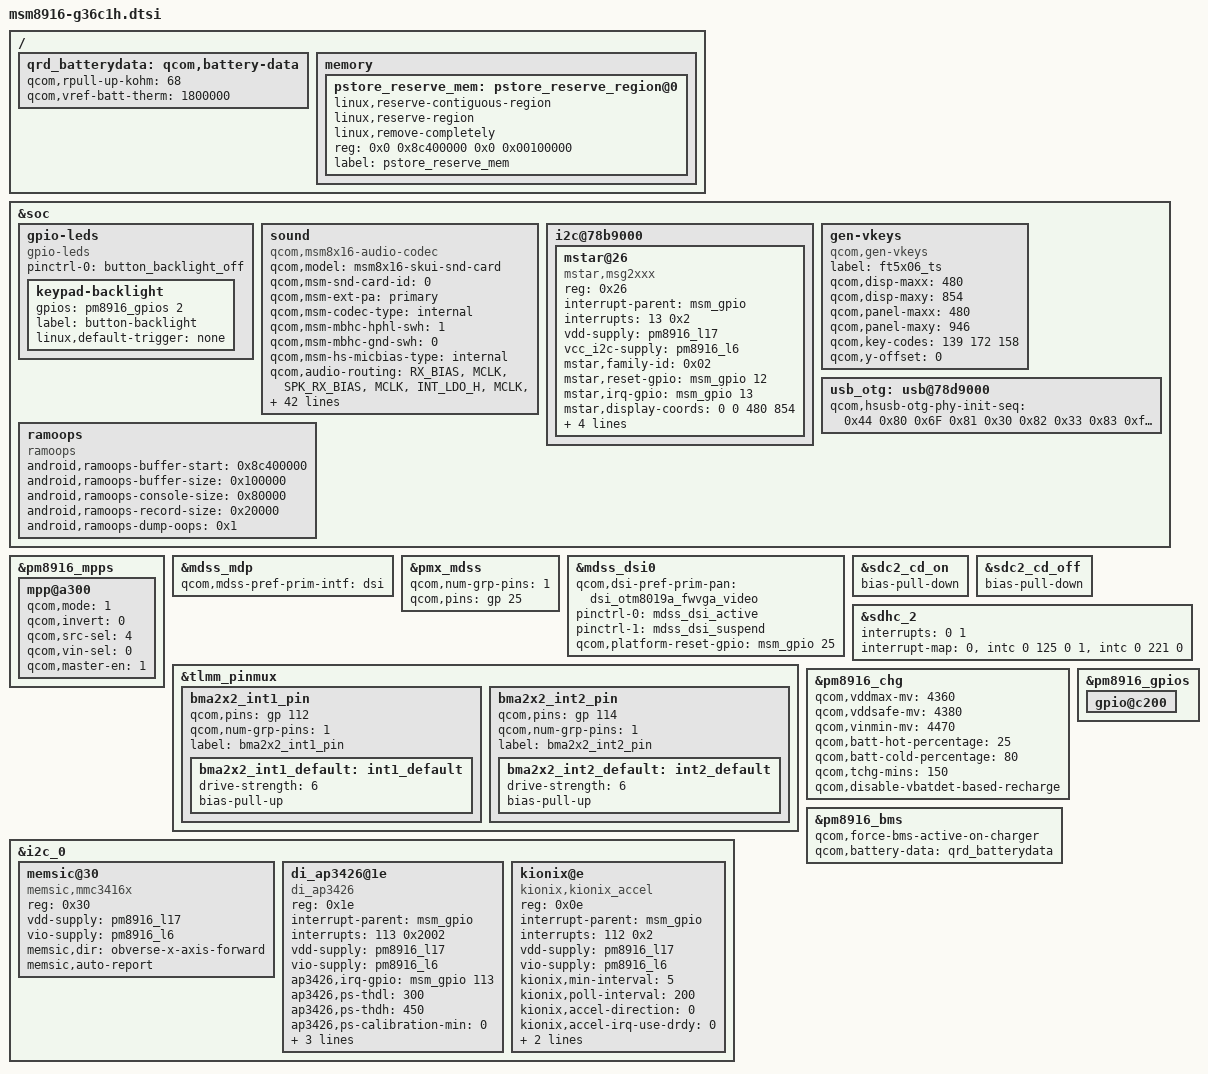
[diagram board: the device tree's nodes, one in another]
/* Copyright (c) 2014, The Linux Foundation. All rights reserved.
 *
 * This program is free software; you can redistribute it and/or modify
 * it under the terms of the GNU General Public License version 2 and
 * only version 2 as published by the Free Software Foundation.
 *
 * This program is distributed in the hope that it will be useful,
 * but WITHOUT ANY WARRANTY; without even the implied warranty of
 * MERCHANTABILITY or FITNESS FOR A PARTICULAR PURPOSE.  See the
 * GNU General Public License for more details.
 */

#include "msm8916-camera-sensor-g36c1h.dtsi"
#include "dsi-panel-ili9806e-fwvga-hsd-helitai-video.dtsi"

&soc {
	gpio-leds {
		compatible = "gpio-leds";
		status = "okay";
		pinctrl-names = "default";
		pinctrl-0 = <&button_backlight_off>;

		keypad-backlight {
			gpios = <&msm_gpio 119 0>;
			label = "button-backlight";
			linux,default-trigger = "none";
		};
	};

	sound {
		compatible = "qcom,msm8x16-audio-codec";
		qcom,model = "msm8x16-skui-snd-card";
		qcom,msm-snd-card-id = <0>;
		qcom,msm-ext-pa = "primary";
		qcom,msm-codec-type = "internal";
		qcom,msm-mbhc-hphl-swh = <1>;
		qcom,msm-mbhc-gnd-swh = <0>;
		qcom,msm-hs-micbias-type = "internal";
		qcom,audio-routing =
			"RX_BIAS", "MCLK",
			"SPK_RX_BIAS", "MCLK",
			"INT_LDO_H", "MCLK",
			"MIC BIAS Internal1", "Handset Mic",
			"MIC BIAS Internal2", "Headset Mic",
			"MIC BIAS Internal1", "Secondary Mic",
			"AMIC1", "MIC BIAS Internal1",
			"AMIC2", "MIC BIAS Internal2",
			"AMIC3", "MIC BIAS Internal1";
		pinctrl-names = "cdc_lines_act",
				"cdc_lines_sus";
		pinctrl-0 = <&cdc_pdm_lines_act>;
		pinctrl-1 = <&cdc_pdm_lines_sus>;
		asoc-platform = <&pcm0>, <&pcm1>, <&voip>, <&voice>,
				<&loopback>, <&compress>, <&hostless>,
				<&afe>, <&lsm>, <&routing>, <&lpa>;
		asoc-platform-names = "msm-pcm-dsp.0", "msm-pcm-dsp.1",
				"msm-voip-dsp", "msm-pcm-voice", "msm-pcm-loopback",
				"msm-compress-dsp", "msm-pcm-hostless", "msm-pcm-afe",
				"msm-lsm-client", "msm-pcm-routing", "msm-pcm-lpa";
		asoc-cpu = <&dai_pri_auxpcm>, <&dai_hdmi>,
				<&dai_mi2s0>, <&dai_mi2s1>, <&dai_mi2s2>, <&dai_mi2s3>,
				<&sb_0_rx>, <&sb_0_tx>, <&sb_1_rx>, <&sb_1_tx>,
				<&sb_3_rx>, <&sb_3_tx>, <&sb_4_rx>, <&sb_4_tx>,
				<&bt_sco_rx>, <&bt_sco_tx>, <&bt_a2dp_rx>,
				<&int_fm_rx>, <&int_fm_tx>,
				<&afe_pcm_rx>, <&afe_pcm_tx>, <&afe_proxy_rx>, <&afe_proxy_tx>,
				<&incall_record_rx>, <&incall_record_tx>, <&incall_music_rx>,
				<&incall_music_2_rx>;
		asoc-cpu-names = "msm-dai-q6-auxpcm.1", "msm-dai-q6-hdmi.8",
				"msm-dai-q6-mi2s.0", "msm-dai-q6-mi2s.1",
				"msm-dai-q6-mi2s.2", "msm-dai-q6-mi2s.3",
				"msm-dai-q6-dev.16384", "msm-dai-q6-dev.16385",
				"msm-dai-q6-dev.16386", "msm-dai-q6-dev.16387",
				"msm-dai-q6-dev.16390", "msm-dai-q6-dev.16391",
				"msm-dai-q6-dev.16392", "msm-dai-q6-dev.16393",
				"msm-dai-q6-dev.12288", "msm-dai-q6-dev.12289",
				"msm-dai-q6-dev.12290", "msm-dai-q6-dev.12292",
				"msm-dai-q6-dev.12293", "msm-dai-q6-dev.224",
				"msm-dai-q6-dev.225", "msm-dai-q6-dev.241",
				"msm-dai-q6-dev.240", "msm-dai-q6-dev.32771",
				"msm-dai-q6-dev.32772", "msm-dai-q6-dev.32773",
				"msm-dai-q6-dev.32770";
		asoc-codec = <&stub_codec>, <&pm8916_tombak_dig>;
		asoc-codec-names = "msm-stub-codec.1", "tombak_codec";
	};

	i2c@78b9000 { /* BLSP1 QUP5 */
		mstar@26{
			compatible = "mstar,msg213xa";
			reg = <0x26>;
			interrupt-parent = <&msm_gpio>;
			interrupts = <13 0x2>;
			vdd-supply = <&pm8916_l17>;
			vcc_i2c-supply = <&pm8916_l6>;
			mstar,family-id = <0x02>;
			mstar,reset-gpio = <&msm_gpio 12 0x00>;
			mstar,irq-gpio = <&msm_gpio 13 0x00>;
			mstar,display-coords = <0 0 480 854>;
			mstar,panel-coords = <0 0 480 946>;
			mstar,button-map= <158 102 139>;
			mstar,no-force-update;
			mstar,i2c-pull-up;
		};
		mstar@26{
			compatible = "mstar,msg26xx";
			reg = <0x26>;
			interrupt-parent = <&msm_gpio>;
			interrupts = <13 0x2>;
			vdd-supply = <&pm8916_l17>;
			vcc_i2c-supply = <&pm8916_l6>;
			mstar,family-id = <0x02>;
			mstar,reset-gpio = <&msm_gpio 12 0x00>;
			mstar,irq-gpio = <&msm_gpio 13 0x00>;
			mstar,display-coords = <0 0 720 1280>;
			mstar,panel-coords = <0 0 720 1380>;
			mstar,button-map= <139 172 158>;
			mstar,no-force-update;
			mstar,i2c-pull-up;
		};
		mstar@26{
			compatible = "mstar,msg2xxx";
			reg = <0x26>;
			interrupt-parent = <&msm_gpio>;
			interrupts = <13 0x2>;
			vdd-supply = <&pm8916_l17>;
			vcc_i2c-supply = <&pm8916_l6>;
			mstar,family-id = <0x02>;
			mstar,reset-gpio = <&msm_gpio 12 0x00>;
			mstar,irq-gpio = <&msm_gpio 13 0x00>;
			mstar,display-coords = <0 0 480 854>;
			mstar,panel-coords = <0 0 480 946>;
			mstar,button-map= <580 158 172>;
			mstar,no-force-update;
			mstar,i2c-pull-up;
		};
	};

	gen-vkeys {
		compatible = "qcom,gen-vkeys";
		label = "ft5x06_ts";
		qcom,disp-maxx = <480>;
		qcom,disp-maxy = <854>;
		qcom,panel-maxx = <480>;
		qcom,panel-maxy = <946>;
		qcom,key-codes = <139 172 158>;
		qcom,y-offset = <0>;
	};

	gpio-leds {
		keypad-backlight {
			gpios = <&pm8916_gpios 2 0>;

		};
	};

	usb_otg: usb@78d9000 {
		qcom,hsusb-otg-phy-init-seq =
			<0x44 0x80 0x6F 0x81 0x30 0x82 0x33 0x83 0xffffffff>;
	};

	ramoops {
		compatible = "ramoops";
		status = "ok";

		android,ramoops-buffer-start = <0x8c400000>;
		android,ramoops-buffer-size = <0x100000>;
		android,ramoops-console-size = <0x80000>;
		android,ramoops-record-size = <0x20000>;
		android,ramoops-dump-oops = <0x1>;
	};
};

&pm8916_mpps {
	mpp@a300 { /* MPP 4 */
		/* Backlight PWM */
		qcom,mode = <1>;		/* Digital output */
		qcom,invert = <0>;		/* Disable invert */
		qcom,src-sel = <4>;		/* DTEST1 */
		qcom,vin-sel = <0>;		/* VPH_PWR */
		qcom,master-en = <1>;		/* Enable MPP */
	};
};

&mdss_mdp {
	qcom,mdss-pref-prim-intf = "dsi";
};

&pmx_mdss {
	qcom,num-grp-pins = <1>;
	qcom,pins = <&gp 25>;
};

&mdss_dsi0 {
	qcom,dsi-pref-prim-pan = <&dsi_otm8019a_fwvga_video>;
	pinctrl-names = "mdss_default", "mdss_sleep";
	pinctrl-0 = <&mdss_dsi_active>;
	pinctrl-1 = <&mdss_dsi_suspend>;

	qcom,platform-reset-gpio = <&msm_gpio 25 0>;
};

&tlmm_pinmux {
	bma2x2_int1_pin {
		qcom,pins = <&gp 112>;
		qcom,num-grp-pins = <1>;
		label = "bma2x2_int1_pin";
		bma2x2_int1_default: int1_default {
			  drive-strength = <6>;
			  bias-pull-up;
		};
	};

	bma2x2_int2_pin {
		qcom,pins = <&gp 114>;
		qcom,num-grp-pins = <1>;
		label = "bma2x2_int2_pin";
		bma2x2_int2_default: int2_default {
			  drive-strength = <6>;
			  bias-pull-up;
		};
	};
};

&i2c_0 { /* BLSP1 QUP2 */
	memsic@30 { /* Magnetic field sensor */
		compatible = "memsic,mmc3416x";
		reg = <0x30>;
		vdd-supply = <&pm8916_l17>;
		vio-supply = <&pm8916_l6>;
		memsic,dir = "obverse-x-axis-forward";
		memsic,auto-report;
	};

	di_ap3426@1e {
		compatible = "di_ap3426";
		reg = <0x1e>;
		interrupt-parent = <&msm_gpio>;
		interrupts = <113 0x2002>;
		vdd-supply = <&pm8916_l17>;
		vio-supply = <&pm8916_l6>;
		ap3426,irq-gpio = <&msm_gpio 113 0x2002>;
		ap3426,ps-thdl = <300>;
		ap3426,ps-thdh = <450>;
		ap3426,ps-calibration-min = <0>;
		ap3426,ps-calibration-expected = <0>;
		ap3426,ps-calibration-max = <500>;
		ap3426,ps-integrated-time = <0x8>;
	};

	kionix@e {
		compatible = "kionix,kionix_accel";
		reg = <0x0e>;
		interrupt-parent = <&msm_gpio>;
		interrupts = <112 0x2>;
		vdd-supply = <&pm8916_l17>;
		vio-supply = <&pm8916_l6>;
		kionix,min-interval = <5>;
		kionix,poll-interval = <200>;
		kionix,accel-direction = <0>;
		kionix,accel-irq-use-drdy = <0>;
		kionix,accel-res = <12>;
		kionix,accel-g-range = <2>;
	};
};

&sdc2_cd_on {
	/delete-property/ bias-pull-up;
	bias-pull-down;
};

&sdc2_cd_off {
	/delete-property/ bias-disable;
	bias-pull-down;
};

&sdhc_2 {
	interrupts = <0 1>;
	interrupt-map = <0 &intc 0 125 0
		1 &intc 0 221 0>;
	interrupt-names = "hc_irq", "pwr_irq";
	/delete-property/ cd-gpios;
};

&pm8916_chg {
	qcom,vddmax-mv = <4360>;
	qcom,vddsafe-mv = <4380>;
	qcom,vinmin-mv = <4470>;
	qcom,batt-hot-percentage = <25>;
	qcom,batt-cold-percentage = <80>;
	qcom,tchg-mins = <150>;
	qcom,disable-vbatdet-based-recharge;
	status = "okay";
};

&pm8916_bms {
	status = "okay";
	qcom,force-bms-active-on-charger;
	qcom,battery-data = <&qrd_batterydata>;

};

/ {
	qrd_batterydata: qcom,battery-data {
		qcom,rpull-up-kohm = <68>;
		qcom,vref-batt-therm = <1800000>;

		#include "batterydata-qrd-wk-4v35-2000mah.dtsi"
	};
};

&pm8916_gpios {
	gpio@c200 { /* GPIO 3 */
		/* External regulator control for WTR */
		status = "ok";
	};
};

/ {
	memory {
		pstore_reserve_mem: pstore_reserve_region@0 {
			linux,reserve-contiguous-region;
			linux,reserve-region;
			linux,remove-completely;
			reg = <0x0 0x8c400000 0x0 0x00100000>;
			label = "pstore_reserve_mem";
		};
	};
};
